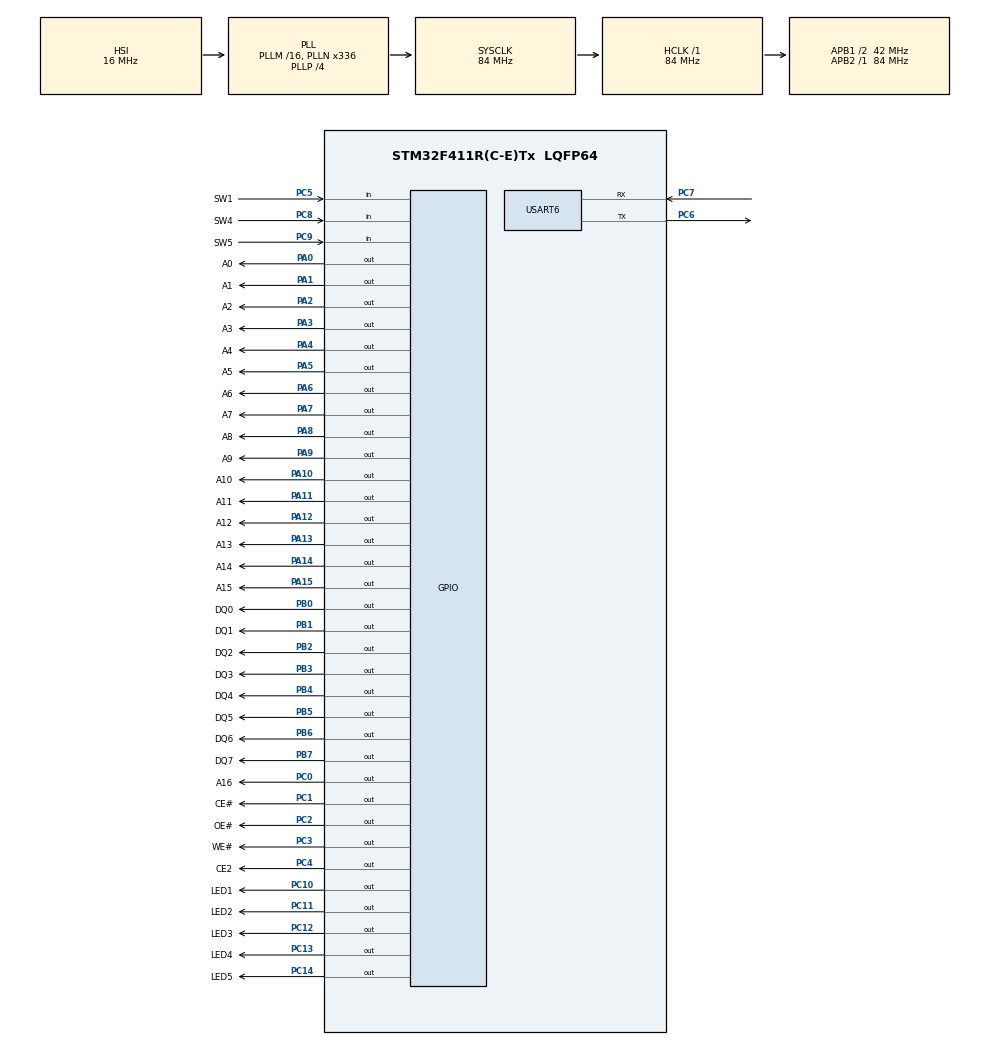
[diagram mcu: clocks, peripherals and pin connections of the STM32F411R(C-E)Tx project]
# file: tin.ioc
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Mcu.Family=STM32F4
Mcu.Name=STM32F411R(C-E)Tx
Mcu.Package=LQFP64
NVIC.PriorityGroup=NVIC_PRIORITYGROUP_0
NVIC.USART6_IRQn=true\:0\:0\:false\:false\:true\:true\:true
PA0-WKUP.GPIO_Label=A0
PA0-WKUP.Signal=GPIO_Output
PA1.GPIO_Label=A1
PA1.Signal=GPIO_Output
PA10.GPIO_Label=A10
PA10.Signal=GPIO_Output
PA11.GPIO_Label=A11
PA11.Signal=GPIO_Output
PA12.GPIO_Label=A12
PA12.Signal=GPIO_Output
PA13.GPIO_Label=A13
PA13.Signal=GPIO_Output
PA14.GPIO_Label=A14
PA14.Signal=GPIO_Output
PA15.GPIO_Label=A15
PA15.Signal=GPIO_Output
PA2.GPIO_Label=A2
PA2.Signal=GPIO_Output
PA3.GPIO_Label=A3
PA3.Signal=GPIO_Output
PA4.GPIO_Label=A4
PA4.Signal=GPIO_Output
PA5.GPIO_Label=A5
PA5.Signal=GPIO_Output
PA6.GPIO_Label=A6
PA6.Signal=GPIO_Output
PA7.GPIO_Label=A7
PA7.Signal=GPIO_Output
PA8.GPIO_Label=A8
PA8.Signal=GPIO_Output
PA9.GPIO_Label=A9
PA9.Signal=GPIO_Output
PB0.GPIO_Label=DQ0
PB0.Signal=GPIO_Output
PB1.GPIO_Label=DQ1
PB1.Signal=GPIO_Output
PB2.GPIO_Label=DQ2
PB2.Signal=GPIO_Output
PB3.GPIO_Label=DQ3
PB3.Signal=GPIO_Output
PB4.GPIO_Label=DQ4
PB4.Signal=GPIO_Output
PB5.GPIO_Label=DQ5
PB5.Signal=GPIO_Output
PB6.GPIO_Label=DQ6
PB6.Signal=GPIO_Output
PB7.GPIO_Label=DQ7
PB7.Signal=GPIO_Output
PC0.GPIO_Label=A16
PC0.Signal=GPIO_Output
PC1.GPIO_Label=CE\#
PC1.Signal=GPIO_Output
PC10.GPIO_Label=LED1
PC10.Signal=GPIO_Output
PC11.GPIO_Label=LED2
PC11.Signal=GPIO_Output
PC12.GPIO_Label=LED3
PC12.Signal=GPIO_Output
PC13-ANTI_TAMP.GPIO_Label=LED4
PC13-ANTI_TAMP.Signal=GPIO_Output
PC14-OSC32_IN.GPIO_Label=LED5
PC14-OSC32_IN.Signal=GPIO_Output
PC2.GPIO_Label=OE\#
PC2.Signal=GPIO_Output
PC3.GPIO_Label=WE\#
PC3.Signal=GPIO_Output
PC4.GPIO_Label=CE2
PC4.Signal=GPIO_Output
PC5.GPIO_Label=SW1
PC5.Signal=GPIO_Input
PC6.Mode=Asynchronous
PC6.Signal=USART6_TX
PC7.Mode=Asynchronous
PC7.Signal=USART6_RX
PC8.GPIO_Label=SW4
PC8.Signal=GPIO_Input
PC9.GPIO_Label=SW5
PC9.Signal=GPIO_Input
ProjectManager.HeapSize=0x200
ProjectManager.StackSize=0x400
ProjectManager.TargetToolchain=STM32CubeIDE
RCC.48MHZClocksFreq_Value=84000000
RCC.AHBFreq_Value=84000000
RCC.APB1CLKDivider=RCC_HCLK_DIV2
RCC.APB1Freq_Value=42000000
RCC.APB1TimFreq_Value=84000000
RCC.APB2Freq_Value=84000000
RCC.APB2TimFreq_Value=84000000
RCC.CortexFreq_Value=84000000
RCC.FLatency-AdvancedSettings=FLASH_LATENCY_2
RCC.HCLKFreq_Value=84000000
RCC.HSE_VALUE=8000000
RCC.HSI_VALUE=16000000
RCC.LSE_VALUE=32768
RCC.PLLN=336
RCC.PLLP=RCC_PLLP_DIV4
RCC.SYSCLKFreq_VALUE=84000000
RCC.SYSCLKSource=RCC_SYSCLKSOURCE_PLLCLK
RCC.VCOOutputFreq_Value=336000000
USART6.VirtualMode=VM_ASYNC
board=NUCLEO-F411RE

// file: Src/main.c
/* USER CODE BEGIN Header */
/**
  ******************************************************************************
  * @file           : main.c
  * @brief          : Main program body
  ******************************************************************************
  * @attention
  *
  * <h2><center>&copy; Copyright (c) 2020 STMicroelectronics.
  * All rights reserved.</center></h2>
  *
  * This software component is licensed by ST under BSD 3-Clause license,
  * the "License"; You may not use this file except in compliance with the
  * License. You may obtain a copy of the License at:
  *                        opensource.org/licenses/BSD-3-Clause
  *
  ******************************************************************************
  */
/* USER CODE END Header */

#include "main.h"

/* USER CODE BEGIN Includes */
#include "commands.h"
#include "usart.h"
#include "gpio.h"
/* USER CODE END Includes */

UART_HandleTypeDef huart6;

void SystemClock_Config(void);
static void MX_GPIO_Init(void);
static void MX_USART6_UART_Init(void);

int main(void)
{

  /* MCU Configuration--------------------------------------------------------*/

  /* Reset of all peripherals, Initializes the Flash interface and the Systick. */
  HAL_Init();

  /* Configure the system clock */
  SystemClock_Config();

  /* Initialize all configured peripherals */
  MX_GPIO_Init();
  MX_USART6_UART_Init();
  /* USER CODE BEGIN 2 */
  USART_Init();
  init_commands();

  /*int address=0;
  char str[100]="0x00";
  	     	sscanf(str, "%x", &address);
  	     	read((uint32_t)address);*/

  /* USER CODE END 2 */

  /* Infinite loop */
  /* USER CODE BEGIN WHILE */
  while (1)
  {

	  CLI_Proc();

    /* USER CODE END WHILE */

  }
}

void SystemClock_Config(void)
{
  RCC_OscInitTypeDef RCC_OscInitStruct = {0};
  RCC_ClkInitTypeDef RCC_ClkInitStruct = {0};

  /** Configure the main internal regulator output voltage
  */
  __HAL_RCC_PWR_CLK_ENABLE();
  __HAL_PWR_VOLTAGESCALING_CONFIG(PWR_REGULATOR_VOLTAGE_SCALE1);
  /** Initializes the CPU, AHB and APB busses clocks
  */
  RCC_OscInitStruct.OscillatorType = RCC_OSCILLATORTYPE_HSI;
  RCC_OscInitStruct.HSIState = RCC_HSI_ON;
  RCC_OscInitStruct.HSICalibrationValue = RCC_HSICALIBRATION_DEFAULT;
  RCC_OscInitStruct.PLL.PLLState = RCC_PLL_ON;
  RCC_OscInitStruct.PLL.PLLSource = RCC_PLLSOURCE_HSI;
  RCC_OscInitStruct.PLL.PLLM = 16;
  RCC_OscInitStruct.PLL.PLLN = 336;
  RCC_OscInitStruct.PLL.PLLP = RCC_PLLP_DIV4;
  RCC_OscInitStruct.PLL.PLLQ = 4;
  if (HAL_RCC_OscConfig(&RCC_OscInitStruct) != HAL_OK)
  {
    Error_Handler();
  }
  /** Initializes the CPU, AHB and APB busses clocks
  */
  RCC_ClkInitStruct.ClockType = RCC_CLOCKTYPE_HCLK|RCC_CLOCKTYPE_SYSCLK
                              |RCC_CLOCKTYPE_PCLK1|RCC_CLOCKTYPE_PCLK2;
  RCC_ClkInitStruct.SYSCLKSource = RCC_SYSCLKSOURCE_PLLCLK;
  RCC_ClkInitStruct.AHBCLKDivider = RCC_SYSCLK_DIV1;
  RCC_ClkInitStruct.APB1CLKDivider = RCC_HCLK_DIV2;
  RCC_ClkInitStruct.APB2CLKDivider = RCC_HCLK_DIV1;

  if (HAL_RCC_ClockConfig(&RCC_ClkInitStruct, FLASH_LATENCY_2) != HAL_OK)
  {
    Error_Handler();
  }
}

static void MX_USART6_UART_Init(void)
{

  huart6.Instance = USART6;
  huart6.Init.BaudRate = 115200;
  huart6.Init.WordLength = UART_WORDLENGTH_8B;
  huart6.Init.StopBits = UART_STOPBITS_1;
  huart6.Init.Parity = UART_PARITY_NONE;
  huart6.Init.Mode = UART_MODE_TX_RX;
  huart6.Init.HwFlowCtl = UART_HWCONTROL_NONE;
  huart6.Init.OverSampling = UART_OVERSAMPLING_16;
  if (HAL_UART_Init(&huart6) != HAL_OK)
  {
    Error_Handler();
  }

}

static void MX_GPIO_Init(void)
{
  GPIO_InitTypeDef GPIO_InitStruct = {0};

  /* GPIO Ports Clock Enable */
  __HAL_RCC_GPIOC_CLK_ENABLE();
  __HAL_RCC_GPIOA_CLK_ENABLE();
  __HAL_RCC_GPIOB_CLK_ENABLE();

  /*Configure GPIO pin Output Level */
  HAL_GPIO_WritePin(GPIOC, LED4_Pin|LED5_Pin|A16_Pin|CE__Pin
                          |OE__Pin|WE__Pin|CE2_Pin|LED1_Pin
                          |LED2_Pin|LED3_Pin, GPIO_PIN_RESET);

  /*Configure GPIO pin Output Level */
  HAL_GPIO_WritePin(GPIOA, A0_Pin|A1_Pin|A2_Pin|A3_Pin
                          |A4_Pin|A5_Pin|A6_Pin|A7_Pin
                          |A8_Pin|A9_Pin|A10_Pin|A11_Pin
                          |A12_Pin|A13_Pin|A14_Pin|A15_Pin, GPIO_PIN_RESET);

  /*Configure GPIO pin Output Level */
  HAL_GPIO_WritePin(GPIOB, DQ0_Pin|DQ1_Pin|DQ2_Pin|DQ3_Pin
                          |DQ4_Pin|DQ5_Pin|DQ6_Pin|DQ7_Pin, GPIO_PIN_RESET);

  /*Configure GPIO pins : LED4_Pin LED5_Pin A16_Pin CE__Pin
                           OE__Pin WE__Pin CE2_Pin LED1_Pin
                           LED2_Pin LED3_Pin */
  GPIO_InitStruct.Pin = LED4_Pin|LED5_Pin|A16_Pin|CE__Pin
                          |OE__Pin|WE__Pin|CE2_Pin|LED1_Pin
                          |LED2_Pin|LED3_Pin;
  GPIO_InitStruct.Mode = GPIO_MODE_OUTPUT_PP;
  GPIO_InitStruct.Pull = GPIO_NOPULL;
  GPIO_InitStruct.Speed = GPIO_SPEED_FREQ_LOW;
  HAL_GPIO_Init(GPIOC, &GPIO_InitStruct);

  /*Configure GPIO pins : A0_Pin A1_Pin A2_Pin A3_Pin
                           A4_Pin A5_Pin A6_Pin A7_Pin
                           A8_Pin A9_Pin A10_Pin A11_Pin
                           A12_Pin A13_Pin A14_Pin A15_Pin */
  GPIO_InitStruct.Pin = A0_Pin|A1_Pin|A2_Pin|A3_Pin
                          |A4_Pin|A5_Pin|A6_Pin|A7_Pin
                          |A8_Pin|A9_Pin|A10_Pin|A11_Pin
                          |A12_Pin|A13_Pin|A14_Pin|A15_Pin;
  GPIO_InitStruct.Mode = GPIO_MODE_OUTPUT_PP;
  GPIO_InitStruct.Pull = GPIO_NOPULL;
  GPIO_InitStruct.Speed = GPIO_SPEED_FREQ_LOW;
  HAL_GPIO_Init(GPIOA, &GPIO_InitStruct);

  /*Configure GPIO pins : SW1_Pin SW4_Pin SW5_Pin */
  GPIO_InitStruct.Pin = SW1_Pin|SW4_Pin|SW5_Pin;
  GPIO_InitStruct.Mode = GPIO_MODE_INPUT;
  GPIO_InitStruct.Pull = GPIO_NOPULL;
  HAL_GPIO_Init(GPIOC, &GPIO_InitStruct);

  /*Configure GPIO pins : DQ0_Pin DQ1_Pin DQ2_Pin DQ3_Pin
                           DQ4_Pin DQ5_Pin DQ6_Pin DQ7_Pin */
  GPIO_InitStruct.Pin = DQ0_Pin|DQ1_Pin|DQ2_Pin|DQ3_Pin
                          |DQ4_Pin|DQ5_Pin|DQ6_Pin|DQ7_Pin;
  GPIO_InitStruct.Mode = GPIO_MODE_OUTPUT_PP;
  GPIO_InitStruct.Pull = GPIO_NOPULL;
  GPIO_InitStruct.Speed = GPIO_SPEED_FREQ_LOW;
  HAL_GPIO_Init(GPIOB, &GPIO_InitStruct);

}

void Error_Handler(void)
{
}

/************************ (C) COPYRIGHT STMicroelectronics *****END OF FILE****/
